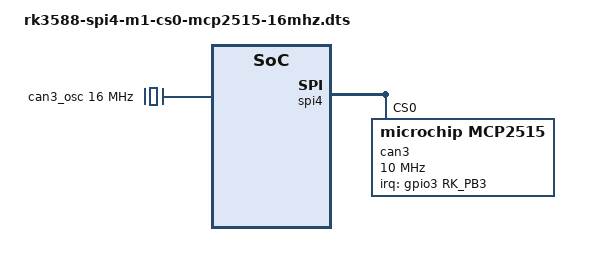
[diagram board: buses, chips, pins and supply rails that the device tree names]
/dts-v1/;
/plugin/;

#include <dt-bindings/gpio/gpio.h>
#include <dt-bindings/pinctrl/rockchip.h>
#include <dt-bindings/interrupt-controller/irq.h>

/ {
	metadata {
		title = "Enable MCP2515 with 16MHz external clock on SPI4-M1 over CS0";
		compatible = "unknown";
		category = "misc";
		description = "Provide support for Microchip MCP2515 SPI CAN controller.\nAssumes 16MHz external clock.\nUses Pin GPIOI3_B3 for INT.";
	};

	fragment@0 {
		target = <&spi4>;
		__overlay__ {
			status = "okay";
			pinctrl-names = "default";
			pinctrl-0 = <&spi4m1_pins &spi4m1_cs0 &spi4m1_cs1>;

			can3: mcp2515@0 {
				compatible = "microchip,mcp2515";
				reg = <0>;
				spi-max-frequency = <10000000>;

				pinctrl-names = "default";
				pinctrl-0 = <&mcp2515_0_int_pins>;

				interrupt-parent = <&gpio3>;
				interrupts = <RK_PB3 IRQ_TYPE_EDGE_FALLING>;

				clocks = <&can3_osc>;
			};
		};
	};

	fragment@1 {
		target = <&pinctrl>;
		__overlay__ {
			mcp2515 {
				mcp2515_0_int_pins: mcp2515-0-int-pins {
					rockchip,pins = <3 RK_PB3 RK_FUNC_GPIO &pcfg_pull_up>;
				};
			};
		};
	};

	fragment@2 {
		target-path = "/";
		__overlay__ {
			can3_osc: can3-osc {
				compatible = "fixed-clock";
				#clock-cells = <0>;
				clock-frequency  = <16000000>;
			};
		};
	};
};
